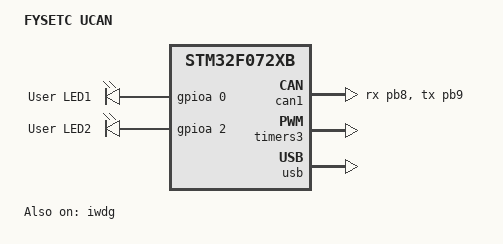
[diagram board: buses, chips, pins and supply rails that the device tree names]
/*
 * Copyright (c) 2017 Clage GmbH
 *
 * SPDX-License-Identifier: Apache-2.0
 */

/dts-v1/;
#include <st/f0/stm32f072Xb.dtsi>
#include <st/f0/stm32f072r(8-b)tx-pinctrl.dtsi>
#include <zephyr/dt-bindings/input/input-event-codes.h>

/ {
	model = "FYSETC UCAN";
	compatible = "fysetc-ucan";

	chosen {
		zephyr,console = &cdc_acm_uart0;
		zephyr,shell-uart = &cdc_acm_uart0;
		zephyr,sram = &sram0;
		zephyr,flash = &flash0;
		zephyr,canbus = &can1;
	};

	leds {
		compatible = "gpio-leds";
		led_1: led_1 {
			gpios = <&gpioa 0 GPIO_ACTIVE_HIGH>;
			label = "User LED1";
		};
		led_2: led_2 {
			gpios = <&gpioa 2 GPIO_ACTIVE_HIGH>;
			label = "User LED2";
		};
	};

	aliases {
		led1 = &led_1;
		led2 = &led_2;
		watchdog0 = &iwdg;
	};
};

&clk_hsi {
	status = "okay";
};

&pll {
	prediv = <1>;
	mul = <6>;
	clocks = <&clk_hsi>;
	status = "okay";
};

&rcc {
	clocks = <&pll>;
	clock-frequency = <DT_FREQ_M(48)>;
	ahb-prescaler = <1>;
	apb1-prescaler = <1>;
};

&can1 {
	pinctrl-0 = <&can_rx_pb8 &can_tx_pb9>;
	pinctrl-names = "default";
	status = "okay";
};

&iwdg {
	status = "okay";
};

&timers3 {
	st,prescaler = <10000>;
	status = "okay";

	pwm3: pwm {
		status = "okay";
		pinctrl-0 = <&tim3_ch1_pc6>;
		pinctrl-names = "default";
	};
};

zephyr_udc0: &usb {
	status = "okay";
	cdc_acm_uart0: cdc_acm_uart0 {
		compatible = "zephyr,cdc-acm-uart";
	};
};
